# HSM_HSM_TRNG_CE00A000h register map
Vendor: Texas Instruments
Peripheral module from a debugger description file (folder AM263P).
Registers are 32-bit, access per field, reset 0x0 unless marked. A register's access mark holds for its fields unless they carry their own. Offsets are as the file gives them; lines under a group give offsets from that group; [hi:lo] are bit positions; {n}, {i} and the like mark numbered series; 'fields as' and 'values as' point back to an identical list; <NAME> marks a mode.

## HSM_TRNG
{0x0+4i} HSM_TRNG_TRNG_INPUT_{i} rw (i=0..3) — These registers are used as input for [SP 800-90A] AES-256 DRBG testing. They share theiraddresses with the TRNG_OUTPUT_0 to TRNG_OUTPUT_3 registers.
  [31:0] TRNG_INPUT — These registers are used as input for [SP 800-90A] AES-256 DRBG testing.
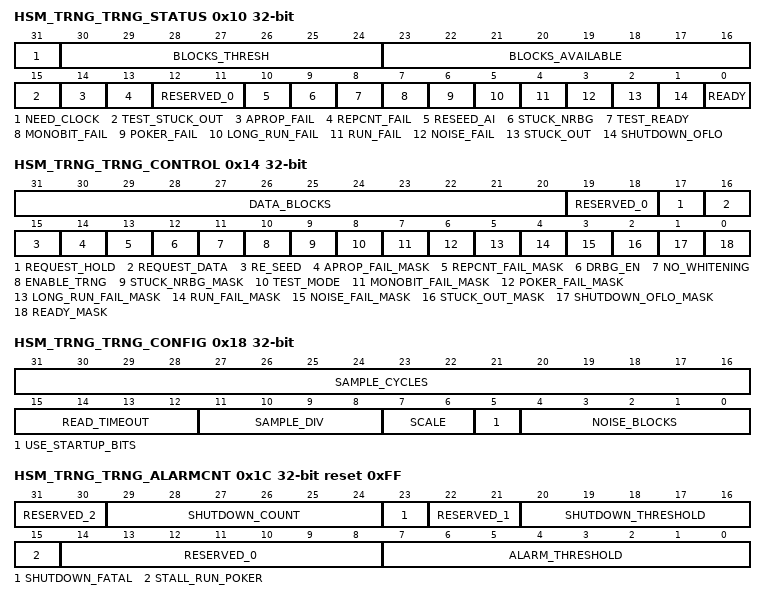
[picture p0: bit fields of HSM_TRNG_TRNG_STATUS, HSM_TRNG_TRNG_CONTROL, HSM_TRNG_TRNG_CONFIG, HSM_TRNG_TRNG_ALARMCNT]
0x10 HSM_TRNG_TRNG_STATUS — Status register.
  [31] NEED_CLOCK ro — 1' indicates that the TRNG is busy generating entropy or is in one of its test modes - the module clock may not be turned off. This bit is a direct mirror of the 'need_clock'output signal of the module.
  [30:24] BLOCKS_THRESH ro — The threshold value for the 'blocks_available' field to indicate 'ready' here. The value iswritten via bits [30:24] of the TRNG_INTACK register. The number of blocks availablein the RAM buffer must be equal to or greater than the value in this field [which iscontrolled by Writing to the TRNG_INTACK register].Note: This field controls the data available interrupt [and status] gating based on thefill level of the RAM buffer. When the interrupt occurs, there is always one extraword available in the output register - with a value of 15 here, the number ofwords that are available is 16 when data ready is indicated.
  [23:16] BLOCKS_AVAILABLE ro — This field indicates the number of 128 bits blocks of random data that are available inthe random data RAM buffer [if configured]. If this value is non-zero, the outputregisters will be re-filled from the random data RAM buffer immediately afteracknowledging the 'ready' interrupt [i.e. after Writing a '1' to bit [0] of theTRNG_INTACK register].
  [15] TEST_STUCK_OUT ro — 1' = indication that 'stuck_out' functionality testing is enabled [via TRNG_INTACKregister bit [15]]. This bit will automatically fall back to '0' when a stuck output isactually detected.
  [14] APROP_FAIL ro — 1' = the [SP 800-90B] 'Adaptive Proportion' test logic monitoring the data shifted intothe main shift register detected too many 8-bit Noise Source output samples matchingthe first sample taken in the test window. Bits [31:30] of the TRNG_SPB_TESTSregister indicate which of the two 'Adaptive Proportion' tests detected the error.Writing a '1' to bit [14] of the TRNG_INTACK register clears this bit to '0', also clearsbits [31:30] of the TRNG_SPB_TESTS register.
  [13] REPCNT_FAIL ro — 1' = the [SP 800-90B] 'Repetition Count' test logic monitoring the data shifted into themain shift register detected a number of consecutive identical 8-bit Noise Source outputsamples that matched the programmed cutoff value. Writing a '1' to bit [13] of theTRNG_INTACK register clears this bit to '0'.
  [12:11] RESERVED_0 wo — Bits should be ignored on a read.
  [10] RESEED_AI ro — For the EIP-76d configurations with BC_DF functionality, this bit indicates when theTRNG_PS_AI_ - registers must be written for an 'Instantiate' or 'Reseed' operation[Writing the highest Byte of the TRNG_PS_AI_11 register then clears this bit]. This bitalso indicates when the DRBG has finished updating its internal Key and V values aftergenerating random data; no specific action is required at that time.Note: This bit is only available for EIP-76d configurations with BC_DF; otherwise, itmust be treated as 'Reserved'.
  [9] STUCK_NRBG ro — 1' = NRBG stuck error; this happens when two identical values were extracted fromthe main shift register [configuration without Conditioning Function] or theConditioning Function output [when configured].
  [8] TEST_READY ro — Multi-purpose bit:> For known-answer tests on the 'Repetition Count', 'Adaptive Proportion','monobit', 'run' and 'poker' tests, BC_DF functionality and Conditioning Function,a '1' indicates that data can be written to the TRNG_RAW_... registers.> When testing the DRBG, a '1' indicates that test data can be written to theTRNG_INPUT_ - registers [for separate AES core testing], result data can be readfrom the TRNG_OUTPUT_ - registers when this bit has become '1' again afterdropping to '0'.> When testing the Noise Source, a '1' indicates that a 64 bit output block from theNoise Source is available for Reading from the TRNG_RAW_... registers, Writing a'1' to the 'test_ready_ack' bit in the TRNG_ACK register will then clear this bitagain.> For the EIP-76d configurations without BC_DF, a '1' here indicates when theTRNG_PS_AI_ - registers can be written to set an Additional Input value for a'Generate' operation. It also indicates when those registers must be written for a'Reseed' operation or [SP 800-90A] DRBG tests. Writing the highest Byte of theTRNG_PS_AI_11 register then clears this bit.Note: For the EIP-76d configurations with BC_DF, the indication that theTRNG_PS_AI_ - registers must be written for an 'Instantiate' or 'Reseed'operation is split off, see bit [10].
  [7] MONOBIT_FAIL ro — 1' = the [AIS-31] 'monobit test' logic monitoring data shifted into the main shiftregister detected an out-of-bounds number of '1's after checking 20,000 bits [test T1 asspecified in the [AIS-31] standard]. Writing a '1' to bit [7] of the TRNG_INTACKregister clears this bit to '0'.Note: This bit is only available if AIS-31 testing logic is configured; otherwise, it mustbe treated as 'Reserved'.
  [6] POKER_FAIL ro — 1' = the [AIS-31] 'poker test' logic monitoring data shifted into the main shift registerdetected an out-of-bounds value in at least one of the 16 'poker_count_X' counters or anout of bounds 'sum of squares' value after checking 20,000 bits [test T2 as specified inthe [AIS-31] standard]. Writing a '1' to bit [6] of the TRNG_INTACK register clears thisbit to '0'.Note: This bit is only available if AIS-31 testing logic is configured; otherwise, it mustbe treated as 'Reserved'.
  [5] LONG_RUN_FAIL ro — 1' = the [AIS-31] 'run test' logic monitoring data shifted into the main shift registerdetected a sequence of 34 identical bits [test T4 as specified in the [AIS-31] standard].Writing a '1' to bit [5] of the TRNG_INTACK register clears this bit to '0'.Note: This bit is only available if AIS-31 testing logic is configured; otherwise, it mustbe treated as 'Reserved'.
  [4] RUN_FAIL ro — 1' = the [AIS-31] 'run test' logic monitoring data shifted into the main shift registerdetected an out-of-bounds value for at least one of the 'run_X_count_...' counters afterchecking 20,000 bits [test T3 as specified in the [AIS-31] standard]. Writing a '1' to bit[4] of the TRNG_INTACK register clears this bit to '0'.Note: This bit is only available if AIS-31 testing logic is configured; otherwise, it mustbe treated as 'Reserved'.
  [3] NOISE_FAIL ro — 1' = the [AIS-31] 'run test' logic monitoring data shifted into the main shift registerdetected a sequence of 48 identical bits, which is considered a 'Noise Source failure' asproposed in section E.5 of the [AIS-31] standard. Writing a '1' to bit [3] of theTRNG_INTACK register clears this bit to '0'.Note: This bit is only available if AIS-31 testing logic is configured; otherwise, it mustbe treated as 'Reserved'.
  [2] STUCK_OUT ro — 1' = logic around the output data registers4 detected that the EIP-76 generates the samevalue twice in a row. The word size for this comparison is 128 bits. Writing a '1' to bit[2] of the TRNG_INTACK register clears this bit to '0'.
  [1] SHUTDOWN_OFLO ro — 1' = the number of FROs shut down after a second 'error event' [i.e. the number of '1'bits in the TRNG_ALARMSTOP register] has exceeded the threshold set by'shutdown_threshold' in the TRNG_ALARMCNT register. Writing a '1' to bit [1] of theTRNG_INTACK register clears this bit to '0'.Note: This bit will be set to '1' when automatic detuning is enabled and an automaticdetuning is performed by the internal logic. In that case, the TRNG is notactually shut down and this bit is informative only.
  [0] READY ro — 1' = data is available in the TRNG_OUTPUT_0 - 3 registers. Acknowledging this stateby Writing a '1' to bit [0] of the TRNG_INTACK register clears this bit to '0'. If a newnumber is already available in the random data buffer, that number is directly movedinto the result register. In this case the 'ready' status bit is asserted again, after at mostsix module clock cycles.
0x14 HSM_TRNG_TRNG_CONTROL — Control register.
  [31:20] DATA_BLOCKS rw — This field indicates the number of 128 bit data blocks that must be generated by the [SP800-90A] AES-256 DRBG in a single 'Generate_function'. It is loaded in a write to thisregister where the 'request_data' bit is '1' [and the 're_seed' bit is '0'] and then countsdown to zero by one for each block that is generated. It is allowed to 'short-cycle' a'Generate_function' by Writing a lower value than already present [even value zero],but Writing a larger value than already present is not allowed [unless the field equalszero]. The maximum number of blocks that can be requested in one go 4095 preventsrequesting too much data in a single 'Generate_function', which is limited by SP 800-90A to generate no more than 219 bits per request.Note: This field is only present when an SP 800-90A DRBG is available.Note: This field covers Bytes 2 and 3 of this register and these Bytes must either bewritten in one go or using the 'request_hold' bit if the Byte write functionality isconfigured [which it is by default].Note: When aborting a 'Generate_function' by Writing zero here, the word beinggenerated at that time is completed normally and stored in the output buffermodule.
  [19:18] RESERVED_0 wo — Bits should be written with '0' and should be ignored on a read.
  [17] REQUEST_HOLD rw — Read/write, this bit can only be set to '1' when the 'data_blocks' field has value zero andByte Writing only bits [23:16], setting the 'request_data' bit to '1' and loading bits[23:20] of the 'data_blocks' field. Value '1' in this bit indicates that bits [31:24] of the'data_blocks' field must be loaded with a separate Byte write, at which point this bit fallsback to '0' and the actual 'Generate_function' is started. Any other write of this registerwith this bit at '1' clears this bit but also clears the buffered 'data_blocks' value.Note: This bit is only present when an [SP 800-90A] AES-256 DRBG is available andByte Writing is configured [the latter is the default].
  [16] REQUEST_DATA rw — Write-only, Writing a '1' indicates that the 'data_blocks' field contains the number of128 bit data blocks that the [SP 800-90A] AES-256 DRBG should generate in a single'Generate_function'. Writing a '0' has no effect.Note: This bit is only present when an SP 800-90A AES-256 DRBG is available andcan only be set to '1' when 'enable_trng' and 'drbg_en' were '1' before thewrite.Note: When Writing a '1' here, only the 'data_blocks' field in this register is changed.Re-seeding takes priority over data generation.Note: When Byte-Writing only bits [23:16] with this bit at '1' and 'request_hold' at '0',bits [31:24] of the 'data_blocks' field are cleared to zeroes.
  [15] RE_SEED rw — Set-only, Writing a '1' starts a 'Reseed' as described in section 5.2.5.4 below, Writing a'0' has no effect.This bit falls back to '0' automatically after the 'Reseed' operation is complete - at thattime the 'block_count' field in the TRNG_BLOCKCNT register is reset to zero and therandom data buffer is zeroized so that any new data read from the EIP-76 will use thenew seed values.Note: This bit is only present when an [SP 800-90A] AES-256 DRBG is available andcan only be set to '1' when 'enable_trng' and 'drbg_en' were '1' before thewrite.Note: When Writing a '1' here, all other bits in this register remain unchanged. Reseedingtakes priority over data generation.
  [14] APROP_FAIL_MASK rw — 1' = allow the 'aprop_fail' bit in the TRNG_STATUS register to activate the [active'high'] 'irq' output.
  [13] REPCNT_FAIL_MASK rw — 1' = allow the 'repcnt_fail' bit in the TRNG_STATUS register to activate the [active'high'] 'irq' output.
  [12] DRBG_EN rw — Enable the [SP 800-90A] AES-256 DRBG. If this bit is reset to '0', the DRBG is forcedback into the idle state immediately.Note: This bit is only present when the SP 800-90A AES-256 DRBG is available andcan only be changed when 'enable_trng' was '0' before the write.To change this bit during operation, it is required to first put the EIP-76 into reset['enable_trng' = 0]. If the DRBG is enabled, it can be disabled by a subsequent write of'0' to 'drbg_en' [Writing this bit when 'enable_trng' is still '1' has no effect, so itrequires TWO writes to this register to disable the DRBG in that case]. The DRBG thenstops immediately. To enable it, the 'drbg_en' bit must be written with '1'. Afterchanging the state, the EIP-76 must be started again by setting the 'enable_trng' bit to'1'. Note that it is required to re-gather entropy, so the same number of start-up cycleswill be used as when starting the EIP-76 out of a system reset state.
  [11] NO_WHITENING rw — The default value of '0' means that toggle-flop whitening of the noise source is enabled.Set this bit to '1' to disable the toggle flip-flop based whitening of the noise source, seesection 3.2 for details. In this mode, the sampling interval is the number of clocksspecified in sample_div multiplied by the factor specified in sample_cycles [and scale].
  [10] ENABLE_TRNG rw — Setting this bit to '1' starts the EIP-76, gathering entropy from the FROs. Resetting thisbit to '0' forces all NRBG logic back into the idle state immediately.For the [SP 800-90A] DRBG option, starting the EIP-76 with the 'drbg_en' bit value '1'performs a CTR_DRBG 'Instantiate' operation [with or without BC_DF, as perconfiguration] with a 'Personalization String' as written to the TRNG_PS_AI_...registers at that time. Resetting this bit to '0' performs the 'Un-instantiate' operation,clearing all internal post-processor registers.
  [9] STUCK_NRBG_MASK rw — 1' = allow the 'stuck_nrbg' bit in the TRNG_STATUS register to activate the [active'high'] 'irq' output.
  [8] TEST_MODE rw — 1' = Enables access to [amongst others] the TRNG_COUNT and TRNG_RAW_L/Hregisters [the latter are cleared before enabling access] and keep 'need_clock' outputactive 'high' for testing purposes. This bit must be set to '1' before various test modesin the TRNG_TEST register can be enabled [see section 5.2.21].
  [7] MONOBIT_FAIL_MASK rw — 1' = allow the 'monobit_fail' bit in the TRNG_STATUS register to activate the [active'high'] 'irq' output.Note: This bit is only available if AIS-31 testing logic is configured, otherwise it mustbe treated as 'Reserved'.
  [6] POKER_FAIL_MASK rw — 1' = allow the 'poker_fail' bit in the TRNG_STATUS register to activate the [active'high'] 'irq' output.Note: This bit is only available if AIS-31 testing logic is configured, otherwise it mustbe treated as 'Reserved'
  [5] LONG_RUN_FAIL_MASK rw — 1' = allow the 'long_run_fail' bit in the TRNG_STATUS register to activate the [active'high'] 'irq' output.Note: This bit is only available if AIS-31 testing logic is configured, otherwise it mustbe treated as 'Reserved'.
  [4] RUN_FAIL_MASK rw — 1' = allow the 'run_fail' bit in the TRNG_STATUS register to activate the [active 'high']'irq' output.Note: This bit is only available if AIS-31 testing logic is configured, otherwise it mustbe treated as 'Reserved'.
  [3] NOISE_FAIL_MASK rw — 1' = allow the 'noise_fail' bit in the TRNG_STATUS register to activate the [active'high'] 'irq' output.Note: This bit is only available if AIS-31 testing logic is configured, otherwise it mustbe treated as 'Reserved'.
  [2] STUCK_OUT_MASK rw — 1' = allow the 'stuck_out' bit in the TRNG_STATUS register to activate the [active'high'] 'irq' output.
  [1] SHUTDOWN_OFLO_MASK rw — 1' = allow the 'shutdown_oflo' bit in the TRNG_STATUS register to activate the [active'high'] 'irq' output.
  [0] READY_MASK rw — 1' = allow the 'ready' bit in the TRNG_STATUS register to activate the [active 'high']'irq' output.
0x18 HSM_TRNG_TRNG_CONFIG rw — Configuration register.
  [31:16] SAMPLE_CYCLES — This field, together with the 'scale' field, defines the number of clock cycles beforeshifting the main shift register and thereby freezing the noise sample. This value mustbe such that there is at least one bit of entropy [in total] in each 8 bits that are shifted.When the 'no_whitening' bit in the TRNG_CONTROL register is set, only the last FROsample is taken and shifted in. When the 'no_whitening' bit is not set, a FRO sample istaken every clock cycle and accumulated via XOR before finally shifting it in.This field can only be modified while 'enable_trng' in TRNG_CONTROL is '0' or wheneither of the 'test_known_noise' or 'test_cond_func' bits in TRNG_TEST is '1'. Value 0 inthis field selects 65536 * 4^scale clock cycles between shifting.
  [15:12] READ_TIMEOUT — This field controls the secure Reading mode [see section 5.2.6.2]. Value 0 disablessecure Reading, values in the range 1 - 15 enable secure Reading and set a read gateclosure timeout of approximately [read_timeout] x 16 'clk' input cycles.This field can only be modified while 'enable_trng' in TRNG_CONTROL is '0'.
  [11:8] SAMPLE_DIV — This field directly controls the number of 'clk' input cycles between samples takenfrom the FROs. The default value 0 indicates that samples are taken every 'clk' cycle,maximum value 15 [decimal] takes one sample every 16 'clk' cycles.This field must be set to a value such that the slowest FRO [even under worst-caseconditions] has a cycle time less than twice the sample period. As delivered, the defaultconfiguration of the FROs should allow this field to remain 0 - this must, however, beconfirmed with post-placement and routing timing analysis.This field can only be modified while 'enable_trng' in TRNG_CONTROL is '0' or wheneither of the 'test_known_noise' or 'test_cond_func' bits in TRNG_TEST is '1'.
  [7:6] SCALE — This field sets the scale factor for the 'sample_cycles' value:0 -> number of XOR-ed FRO samples equals 'sample_cycles'1 -> number of XOR-ed FRO samples equals 'sample_cycles' x 42 -> number of XOR-ed FRO samples equals 'sample_cycles' x 163 -> number of XOR-ed FRO samples equals 'sample_cycles' x 64This field can only be modified while 'enable_trng' in TRNG_CONTROL is '0' or wheneither of the 'test_known_noise' or 'test_cond_func' bits in TRNG_TEST is '1'.
  [5] USE_STARTUP_BITS — Do not discard the first 512 bits of raw data. This reduces the start-up time, but maymore frequently cause start-up health test failures.For configurations without Conditioning function: When enabled, the first 128 bits willstill be discarded instead.
  [4:0] NOISE_BLOCKS — This field sets the number of 512-bit blocks of raw Noise Source output data that mustbe processed by either the Conditioning Function or the SP 800-90 DRBG 'BC_DF'functionality to yield a 'full entropy' output value. As according to [SP 800-90B] theamount of entropy input to this functionality must be twice the amount that is outputand the 8-bit samples output by the Noise Source are supposed to have one bit ofentropy each, the settings for this field are as follows:> SHA-1 Conditioning Function: generates 160 bits output, requiring2560samplebits, equivalent to 5 blocks of raw Noise Source input.> SHA-256 Conditioning Function: generates 256 bits output, requiring4096samplebits, equivalent to 8 blocks of raw Noise Source input. Note that two blocks of 256bits are needed to 'Instantiate' or 'Reseed' the SP 800-90 DRBG [in the EIP-76d-*-SHA2 configurations].> SP 800-90 DRBG 'BC_DF' functionality: generates 384 bits output, requiring6144sample bits, equivalent to 12 blocks of raw Noise Source input.This field can only be modified while 'enable_trng' in TRNG_CONTROL is '0' or wheneither of the 'test_known_noise' or 'test_cond_func' bits in TRNG_TEST is '1'. Value 0 inthis field selects 32 blocks of 512 bits to be processed.
0x1C HSM_TRNG_TRNG_ALARMCNT reset 0xFF — Shutdown interr. ctrl register.
  [31:30] RESERVED_2 wo — Bits should be written with a '0' and should be ignored on a read.
  [29:24] SHUTDOWN_COUNT rw — Read-only, indicates the number of '1' bits in the TRNG_ALARMSTOP register.This field is 6 bits wide to allow up to 32 'ones' to be indicated. The actual maximumvalue equals the number of FROs.
  [23] SHUTDOWN_FATAL rw — 1' = Consider the 'shutdown_oflo' interrupt as a fatal error requiring taking the completeTRNG engine off-line
  [22:21] RESERVED_1 wo — Bits should be written with a '0' and should be ignored on a read.
  [20:16] SHUTDOWN_THRESHOLD rw — Threshold setting for generating the 'shutdown_oflo' interrupt, which is activated whenthe 'shutdown_count' value in this register exceeds the threshold value set here.
  [15] STALL_RUN_POKER rw — 1' = Stall the 'monobit test', 'run test' and 'poker test' circuits when either the'monobit_fail', 'run_fail' or 'poker_fail' bits in the TRNG_STATUS register are set to '1' - this allows inspecting the state of the result counters [which would otherwise be resetimmediately for the next 20,000 bits block to test].
  [14:8] RESERVED_0 wo — Bits should be written with a '0' and should be ignored on a read.
  [7:0] ALARM_THRESHOLD rw — Alarm detection threshold for the repeating pattern detectors on each FRO. A FRO'alarm event' is declared when a repeating pattern [of up to four samples length] isdetected continuously for the number of samples defined by this field's value. Resetvalue 255 [decimal] should keep the number of 'alarm events' to a manageable level.
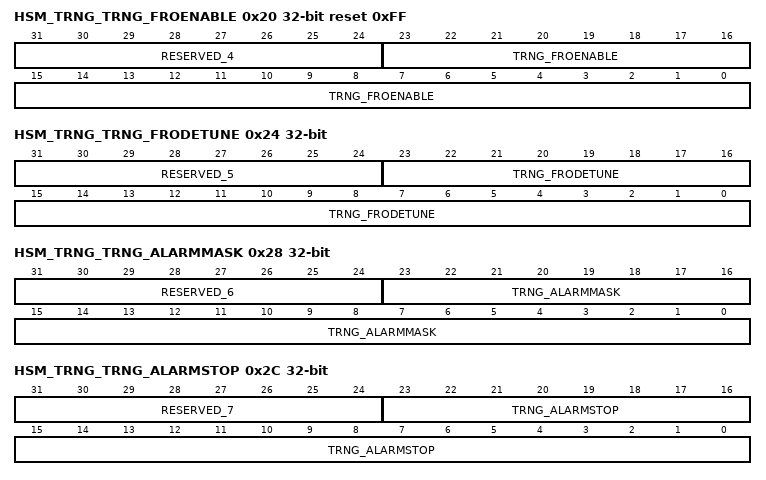
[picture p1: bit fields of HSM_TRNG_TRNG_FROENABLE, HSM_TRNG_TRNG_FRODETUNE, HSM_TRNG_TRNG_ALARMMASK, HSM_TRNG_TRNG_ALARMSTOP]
0x20 HSM_TRNG_TRNG_FROENABLE reset 0xFF — FRO enables register.
  [31:24] RESERVED_4 wo — Bits should be written with a '0' and should be ignored on a read.
  [23:0] TRNG_FROENABLE rw — Enable bits for the individual FROs. A '1' in bit [n] enables FRO 'n'. The default stateis all ones to enable all FROs after power-up. Note that they are not actually started upbefore the 'enable_trng' bit in the TRNG_CONTROL register is set to '1'. A bit isautomatically forced to '0' here [and cannot be written to '1'] when the correspondingbit in the TRNG_ALARMSTOP register has value '1'.
0x24 HSM_TRNG_TRNG_FRODETUNE — FRO de-tune bits register.
  [31:24] RESERVED_5 wo — Bits should be written with a '0' and should be ignored on a read.
  [23:0] TRNG_FRODETUNE rw — De-tune bits for the individual FROs. A '1' in bit [n] lets FRO 'n' run approximately5 0.000000aster. The value of one of these bits may only be changed while the correspondingFRO is turned off [by temporarily Writing a '0' in the corresponding bit of theTRNG_FROENABLE register].
0x28 HSM_TRNG_TRNG_ALARMMASK — Alarm event log register.
  [31:24] RESERVED_6 wo — Bits should be written with a '0' and should be ignored on a read.
  [23:0] TRNG_ALARMMASK rw — Logging bits for the 'alarm events' of individual FROs. A '1' in bit [n] indicates FRO'n' experienced an 'alarm event'.
0x2C HSM_TRNG_TRNG_ALARMSTOP — Alarm shutdown register.
  [31:24] RESERVED_7 wo — Bits should be written with a '0' and should be ignored on a read.
  [23:0] TRNG_ALARMSTOP rw — Logging bits for the 'alarm events' of individual FROs. A '1' in bit [n] indicates FRO'n' experienced more than one 'alarm event' in quick succession and has been turnedoff. A '1' in this field forces the corresponding bit in the TRNG_FROENABLE registerto '0'.
0x30 HSM_TRNG_TRNG_RAW_L rw — Raw noise bits [31:0].
  [31:0] TRNG_RAW_L — When 'test_mode' in TRNG_CONTROL = '1', 'test_noise' in TRNG_TEST = '1' and'test_shiftreg' in TRNG_TEST = '0': read-only access to the main shift register's readbuffer register bits [31:0].When 'test_mode' in TRNG_CONTROL = '1', 'test_noise' in TRNG_TEST = '1' and'test_shiftreg' in TRNG_TEST = '1': read-only access to main shift register bits [31:0].When 'test_mode' in TRNG_CONTROL = '1' and 'test_known_noise' in TRNG_TEST ='1': write-only access to main shift register bits [31:0] [read buffer register bits [31:0]are also written with the same value but generally not used].
0x34 HSM_TRNG_TRNG_RAW_H rw — Raw noise bits [63:32].
  [31:0] TRNG_RAW_H — When 'test_mode' in TRNG_CONTROL = '1', 'test_noise' in TRNG_TEST = '1' and'test_shiftreg' in TRNG_TEST = '0': read-only access to the main shift register's readbuffer register bits [63:32].When 'test_mode' in TRNG_CONTROL = '1', 'test_noise' in TRNG_TEST = '1' and'test_shiftreg' in TRNG_TEST = '1': read-only access to main shift register bits [63:32].When 'test_mode' in TRNG_CONTROL = '1' and 'test_known_noise' in TRNG_TEST ='1': write-only access to main shift register bits [63:32] [read buffer register bits [63:32]are also written with the same value value but generally not used].
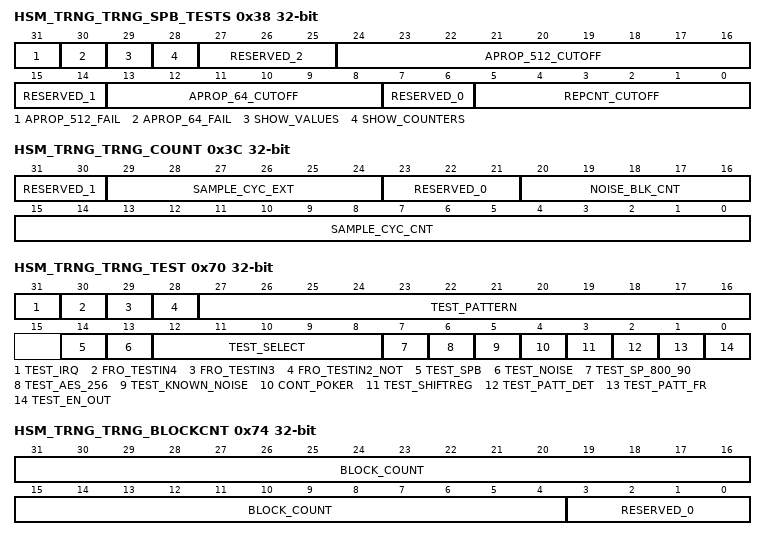
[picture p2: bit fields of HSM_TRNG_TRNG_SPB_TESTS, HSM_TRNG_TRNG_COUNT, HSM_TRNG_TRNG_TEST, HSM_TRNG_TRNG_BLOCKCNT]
0x38 HSM_TRNG_TRNG_SPB_TESTS — SP 800-90B tests control/state.
  [31] APROP_512_FAIL rw — Bit indicating that the 'aprop_512_counter' was equal to the 'aprop_512_cutoff' setting.The state of this bit is OR-ed with the 'aprop_64_fail' bit into the 'aprop_fail' bit in theTRNG_STATUS register and cleared to '0' when Writing a '1' to the 'aprop_fail_ack' bitof the TRNG_INTACK register. While normally read-only, this bit can be written when'test_spb' in TRNG_TEST is '1'.
  [30] APROP_64_FAIL rw — Bit indicating that the 'aprop_64_counter' was equal to the 'aprop_64_cutoff' setting. Thestate of this bit is OR-ed with the 'aprop_512_fail' bit into the 'aprop_fail' bit in theTRNG_STATUS register and cleared to '0' when Writing a '1' to the 'aprop_fail_ack' bitof the TRNG_INTACK register. While normally read-only, this bit can be written when'test_spb' in TRNG_TEST is '1'.
  [29] SHOW_VALUES rw — Bit controlling what is actually accessible in this register; can only be set to '1' when'test_spb' in TRNG_TEST is '1'. When Writing this bit to a different value, all other bitsin this register are preserved.When Writing both 'show_counters' and 'show_values' with a '1' while 'test_spb' inTRNG_TEST is '1', all bits in this register are preserved but the 12-bit internal cyclecounter for the 'Adaptive Proportion' tests is reset to its initial state.
  [28] SHOW_COUNTERS rw — Bit controlling what is actually accessible in this register; can only be set to '1' when'show_values' is written '0' and 'test_spb' in TRNG_TEST is '1'. When Writing this bitto a different value all other bits in this register are preserved.When Writing both 'show_counters' and 'show_values' with a '1' while 'test_spb' inTRNG_TEST is '1', all bits in this register are preserved but the 12-bit internal cyclecounter for the 'Adaptive Proportion' tests is reset to its initial state.
  [27:25] RESERVED_2 wo — Bits should be written with a '0' and should be ignored on a read while 'show_values'equals '1'.
  [24:16] APROP_512_CUTOFF rw — Adaptive Proportion' test cutoff value for the 512 Noise Source samples window sizetest, accessible when 'show_counters' and 'show_values' are both '0'. The reset value of325 corresponds to the cutoff value for a false positive rate of 2-30 and 1 bit of entropyper 8-bit Noise Source sample. This field can only be modified while 'enable_trng' inTRNG_CONTROL is '0' or 'test_spb' in TRNG_TEST is '1'. Value 0 in this fielddisables the 'Adaptive Proportion' test with 512 Noise Source samples window size.
  [15:14] RESERVED_1 wo — Bits should be written with a '0' and should be ignored on a read while 'show_values'equals '0'.
  [13:8] APROP_64_CUTOFF rw — Adaptive Proportion' Noise Source sample compare value for the 64 Noise Sourcesamples window size test, accessible when 'show_values' is '1'. This field is writeablefor testing purposes.
  [7:6] RESERVED_0 wo — Bits should be written with a '0' and should be ignored on a read while 'show_values'equals '0'.
  [5:0] REPCNT_CUTOFF rw — Repetition Count' test cutoff value, accessible when 'show_counters' and 'show_values'are both '0'. The reset value of 31 corresponds to the cutoff value for a false positiverate of 2-30 and 1 bit of entropy per 8-bit Noise Source sample. This field can only bemodified while 'enable_trng' in TRNG_CONTROL is '0' or 'test_spb' in TRNG_TEST is'1'. Value 0 in this field disables the 'Repetition Count' test.
0x3C HSM_TRNG_TRNG_COUNT — Main timing counters register.
  [31:30] RESERVED_1 wo — Bits should be written with a '0' and should be ignored on a read.
  [29:24] SAMPLE_CYC_EXT rw — Extension bits for the sample cycle counter, used when the 'scale' field in theTRNG_CONFIG register is non-zero. This counter can only be accessed when the'test_mode' bit in TRNG_CONTROL is set to '1'.
  [23:21] RESERVED_0 wo — Bits should be written with a '0' and should be ignored on a read.
  [20:16] NOISE_BLK_CNT rw — Noise blocks counter used to control the number of 512-bits noise blocks to be handledby the SHA-1/SHA-256 Conditioning Function or BC_DF functionality in the SP 800-90A DRBG [depending on configuration]. The start value of this counter is 1, which isalso the value to which it is reset when it reaches the value of the 'noise_blocks' field inthe TRNG_CONFIG register. This counter can only be accessed when 'test_mode' bit inTRNG_CONTROL is set to '1', restricted to read-only accesses when the 'test_noise' bitin the TRNG_TEST register is '1'.
  [15:0] SAMPLE_CYC_CNT rw — Lowest 16 bits of the sample cycle counter used to control the number of [XOR-ed]FRO samples that are XOR-ed together into a single noise bit. The start value of thiscounter is 1, which is also the value to which it is reset when it reaches the valuedefined by the 'sample_cycles' and 'scale' fields in the TRNG_CONFIG register. Thiscounter can only be accessed when the 'test_mode' bit in TRNG_CONTROL is set to '1'.Note: If the 'no_whitening' bit in the TRNG_CONTROL register is set to '1', the XORingof FRO samples is not done; the noise bit is then the last FRO sample of theinterval timed by this counter.
0x40 HSM_TRNG_TRNG_PS_AI_0 wo — DRBG input (LSW).
  [31:0] VECTOR — Bits [31:0] of the SP 800-90A 'Personalization String'/'Nonce' [Instantiate function] or'Additional Input' [Reseed and Generate functions]. This register is only availablewhen an SP 800-90A DRBG is configured.
{0x40+4i} HSM_TRNG_TRNG_PS_AI_{i} wo (i=1..3) — DRBG input.
  [31:0] VECTOR — Bits [{32i+31}:{32i}] of the SP 800-90A 'Personalization String'/'Nonce' [Instantiate function]or 'Additional Input' [Reseed and Generate functions]. This register is only availablewhen an SP 800-90A DRBG is configured.
0x50 HSM_TRNG_TRNG_PS_AI_4 wo — DRBG input.
  [31:0] VECTOR — Bits [159:128] of the SP 800-90 'Personalization String'/'Nonce' [Instantiate function]or 'Additional Input' [Reseed and Generate functions]. This register is only availablewhen an SP 800-90 DRBG is configured.
0x54 HSM_TRNG_TRNG_PS_AI_5 wo — DRBG input.
  [31:0] VECTOR — Bits [191:160] of the SP 800-90A 'Personalization String'/'Nonce' [Instantiate function]or 'Additional Input' [Reseed and Generate functions]. This register is only availablewhen an SP 800-90A DRBG is configured.
0x58 HSM_TRNG_TRNG_PS_AI_6 wo — DRBG input.
  [31:0] VECTOR — Bits [223:192] of the SP 800-90A 'Personalization String'/'Nonce' [Instantiate function]or 'Additional Input' [Reseed and Generate functions]. This register is only availablewhen an SP 800-90A DRBG is configured.
0x5C HSM_TRNG_TRNG_PS_AI_7 wo — DRBG input.
  [31:0] VECTOR — Bits [255:224] of the SP 800-90 'Personalization String'/'Nonce' [Instantiate function]or 'Additional Input' [Reseed and Generate functions]. This register is only availablewhen an SP 800-90 DRBG is configured.
0x60 HSM_TRNG_TRNG_PS_AI_8 wo — DRBG input.
  [31:0] VECTOR — Bits [287:256] of the SP 800-90A 'Personalization String'/'Nonce' [Instantiate function]or 'Additional Input' [Reseed and Generate functions]. This register is only availablewhen an SP 800-90A DRBG is configured.
0x64 HSM_TRNG_TRNG_PS_AI_9 wo — DRBG input.
  [31:0] VECTOR — Bits [319:288] of the SP 800-90 'Personalization String'/'Nonce' [Instantiate function]or 'Additional Input' [Reseed and Generate functions]. This register is only availablewhen an SP 800-90 DRBG is configured.
0x68 HSM_TRNG_TRNG_PS_AI_10 wo — DRBG input.
  [31:0] VECTOR — Bits [351:320] of the SP 800-90A 'Personalization String'/'Nonce' [Instantiate function]or 'Additional Input' [Reseed and Generate functions]. This register is only availablewhen an SP 800-90A DRBG is configured.
0x6C HSM_TRNG_TRNG_PS_AI_11 wo — DRBG input (MSW).
  [31:0] VECTOR — Bits [383:352] of the SP 800-90A 'Personalization String'/'Nonce' [Instantiate function]or 'Additional Input' [Reseed and Generate functions]. This register is only availablewhen an SP 800-90A DRBG is configured.Note: This register must be written with a [dummy] value for a 'Reseed' operation tocomplete. For BC_DF configurations, it must also be written for an'Instantiate' function.
0x70 HSM_TRNG_TRNG_TEST rw — Test control register.
  [31] TEST_IRQ — 1' = force 'irq' output 'high' for interrupt signal connectivity testing.
  [30] FRO_TESTIN4 — Control bit driving the 'fro_testin4' output of the TRNG module, which connects to allthe select inputs on the test multiplexers in the FROs [see Figure 3]. The actual outputhas the state of this bit, so a '0' selects the output of the delay control multiplexers. A'1' here also forces the 'fro_enable[n]' output [with n equal to the value of the'test_select' field here] to '1' - this allows testing the signal path through the AND-ORINVERTgate in the FROs.This bit can only be set to '1' when 'test_mode' in TRNG_CONTROL is '1' too.
  [29] FRO_TESTIN3 — Control bit driving the 'fro_testin3' output of the TRNG module, which connects to allthe OR inputs on the AND-OR gates in the FRO chains [see Figure 3]. The actualoutput has the state of this bit, so a '0' does not disturb the operation of the FROs.This bit can only be set to '1' when 'test_mode' in TRNG_CONTROL is '1' too.
  [28] FRO_TESTIN2_NOT — Control bit driving the 'fro_testin2' output of the TRNG module, which connects to allthe AND inputs on the AND-OR gates in the FRO chains [see Figure 3]. The actualoutput is the complement of this bit, so a '0' does not disturb the operation of the FROs.This bit can only be set to '1' when 'test_mode' in TRNG_CONTROL is '1' too.
  [27:16] TEST_PATTERN — Repeating sequence of bits to be fed into the selected FRO delay chain ['test_patt_fro' ='1'] and/or the selected FRO error detection circuit ['test_patt_det' = '1']. This field isrotated right over one bit, once every sample period, when either of these control bits is'1'. Therefore, bit [16] is the actual pattern bit fed into the test target.
  [14] TEST_SPB — 1' = Enable testing of the [SP 800-90B] 'Repetition Count' and 'Adaptive Proportion'tests by allowing the 'show_counters' and 'show_values' bits in the TRNG_SPB_TESTSregister to be set non-zero. To perform Known Answer Tests on those functions, the'test_known_noise' bit in this register must be set to '1' too. The 'need_clock' output isforced active while this bit is '1'. See section 5.2.21.2 below for more information.This bit can only be set to '1' when 'test_mode' in TRNG_CONTROL is '1' too.
  [13] TEST_NOISE — 1' = Enable Noise Source testing, making 64 bit blocks of Noise Source outputavailable in the TRNG_RAW_... registers. When 'test_shiftreg' is '0', these must beacknowledged by Writing a '1' to the 'test_ready_ack' bit in the TRNG_ACK register.The 'need_clock' output is forced active while this bit is '1'.This bit can only be set to '1' when 'test_mode' in TRNG_CONTROL is '1' and'test_known_noise' is written with a '0'.
  [12:8] TEST_SELECT — Number of the FRO to be tested, value should be in range 0 - 23 for the defaultconfiguration of 24 FROs.
  [7] TEST_SP_800_90 — 1' = Provide direct access to the [SP 800-90A] DRBG [EIP-76d] for NIST compliantknown-answer tests [DRBG state is lost during testing]. The 'need_clock' output isforced active while this bit is '1'. See section 5.2.21.4 below for more information.This bit is only present when an [SP 800-90A] DRBG is available [EIP-76d] and canonly be set to '1' when the 'drbg_en' bit in the TRNG_CONTROL register is '1' and the'test_aes_256' bit in this register is '0' before the write. For an EIP-76 configurationwithout BC_DF, an added restriction is that the 'test_known_noise' bit in this register is'0'. For configurations that include BC_DF, this test is done using known noise input tothat function, so the 'test_known_noise' bit must be '1' to set this bit.
  [6] TEST_AES_256 — Dual purpose bit that is only present when an [SP 800-90A] DRBG is available [EIP-76d] and can only be set to '1' when the 'drbg_en' bit in the TRNG_CONTROL registeris '1' and the 'test_known_noise' bit in this register is '0'.When 'test_sp_800_90' is '0':'1' = Provide direct access to the [SP 800-90A] DRBG AES-256 crypto core forknown-answer tests. The 'need_clock' output is forced active while this bit is '1'.This test mode uses TRNG_KEY_0 - TRNG_KEY_7 as key registers. Data writtento the TRNG_INPUT_ - registers is AES-ECB encrypted to the TRNG_OUTPUT_ - registers and the DRBG state is fully preserved while doing so. See section 5.2.21.4below for more information.When 'test_sp_800_90' is '1' and BC_DF functionality is not available:'0' = perform fixed sequence SP 800-90A known answer tests, each consisting ofan 'Instantiate' followed by a 'Generate with Prediction Resistance' operation.'1' = perform variable sequence SP 800-90A known answer tests, each consistingof an 'Instantiate' operation followed by any sequence of 'Reseed' and variablelength 'Generate' operations. These 'Generate' operations can be done with orwithout 'Additional Input'.While 'test_sp_800_90' is '1', 'test_aes_256' cannot be changed. 'test_aes_256' willbe forced to '0' when 'test_sp_800_90' is cleared again.
  [5] TEST_KNOWN_NOISE — 1' = Allow Writing of known test data into the main shift register [Writing input data inchunks of 64 bits to the TRNG_RAW_L and TRNG_RAW_H registers] and allow Writingof the 'noise_blocks', 'sample_interval' and 'sample_cycles' fields in the TRNG_CONFIGregister. This allows testing the [SP 800-90B] 'Repetition Count' and 'AdaptiveProportion' tests, the [optional] [AIS-31] run, poker and monobit tests, the [optional]Conditioning Function and the [SP 800-90A] BC_DF function [if configured]. Whilethis bit is '1', the Noise Source is not allowed to generate entropy but any bufferedrandom data is preserved, to be loaded into the output registers as soon as this bit isreset to '0' again. The 'need_clock' output is forced active while this bit is '1'. Allcircuits using or monitoring data in the main shift register are reset to their initial stateson any change of this bit. See section 5.2.21.1 below for more information.This bit can only be set to '1' when 'test_mode' in TRNG_CONTROL is '1' too.
  [4] CONT_POKER — 1' = Keep 'monobit test' and 'poker test' running continuously by not resetting the'monobit_count' and 'poker_count_X' counters at the end of each 20,000 bits test block.This bit can only be set to '1' when 'test_mode' in TRNG_CONTROL is '1' too.
  [3] TEST_SHIFTREG — 1' = Read directly from the main shift register when 'test_noise' is set to '1', '0' = readfrom the shift register buffer [using the 'test_ready' bit in the TRNG_STATUS register toindicate that a new batch of 64 bits can be read].This bit can only be set to '1' when 'test_mode' in TRNG_CONTROL is '1' too.
  [2] TEST_PATT_DET — 1' = Repeatedly feed 'test_pattern' into the error detection circuit of the FRO selectedby the 'test_select' field.This bit can only be set to '1' when 'test_mode' in TRNG_CONTROL is '1' too.
  [1] TEST_PATT_FR — 1' = Repeatedly feed 'test_pattern' into the delay chain of the FRO selected by the'test_select' field by forcing the corresponding 'fro_enable' output 'low' and forcingthe corresponding 'fro_testin' output to the state of bit [16] of this register.This bit can only be set to '1' when 'test_mode' in TRNG_CONTROL is '1' too.
  [0] TEST_EN_OUT — 1' = Enable the 'tst_fro_clk_out' output, connecting to the FRO selected by the'test_select' field.This bit can only be set to '1' when 'test_mode' in TRNG_CONTROL is '1' too.
0x74 HSM_TRNG_TRNG_BLOCKCNT — Output blocks counter.
  [31:4] BLOCK_COUNT rw — Counter for the number of 128-bit blocks generated by the DRBG. It is forced back tozero when the DRBG is disabled and cleared to zero when an internal 'Reseed'operation has finished. This register can be used by driver software to determine whento 'Reseed' the DRBG.The whole 32 bits of this register represent the amount of data [in bytes] generated sincethe last 'Reseed'.
  [3:0] RESERVED_0 wo — Bits should be written with a '0' and should be ignored on a read.
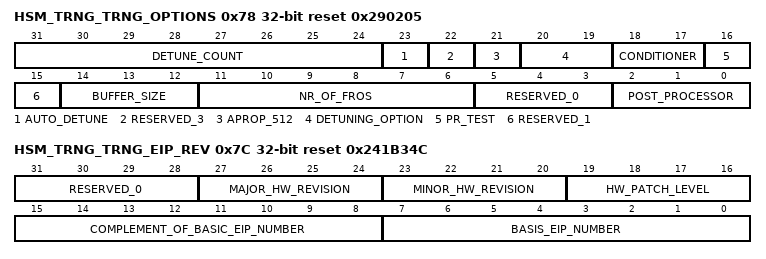
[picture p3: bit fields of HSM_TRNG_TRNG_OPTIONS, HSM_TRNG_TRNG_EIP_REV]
0x78 HSM_TRNG_TRNG_OPTIONS reset 0x290205 — Engine options information.
  [31:24] DETUNE_COUNT rw — Indicates the number of detune events that occurred on the enabled FROs. The counteris incremented by one on each detune event up to a value 255. The counter will remainat 255 when more detune events occur. The counter can be cleared by Writing value0xFF to this field [any other value has no effect].
  [23] AUTO_DETUNE rw — When written with '1', automatic detuning is enabled. For the 'basic' functionality, thedetuning is done when 'shutdown_count' exceeds 'shutdown_threshold'. At that pointFROs that have a '1' in the TRNG_ALARMSTOP register are re-enabled in theTRNG_FROENABLE register, have their detune bit flipped in the TRNG_FRODETUNEregister and their bits cleared in the TRNG_ALARMMASK and TRNG_ALARMSTOPregisters. Also, the 'shutdown_oflo' bit in the TRNG_STATUS register will be set to '1'to indicate automatic detuning has been performed.Note: This bit can only be set to '1' when the 'shutdown_fatal' field ofTRNG_ALARMCNT is configured with '0'.
  [22] RESERVED_3 wo — Bits should be ignored on a read.
  [21] APROP_512 ro — 0: [legacy] The Adaptive Proportion test works with a window size of4096bit, whichwas the size for earlier draft versions of [SP 800-90B].1:[default] The Adaptive Proportion test works with a window size of 512 bits, asspecified in [SP 800-90B].
  [20:19] DETUNING_OPTION ro — 0: no automatic detuning functionality is present1:'basic' detuning functionality is present. Default for all standard configurations.Other values are reserved
  [18:17] CONDITIONER ro — 0: no Conditioning Function is present or a BC_DF Conditioning Function is presentwhen an AES DRBG is present as well.1:a SHA1-based Conditioning Function is present.2:a SHA-256 based Conditioning Function is present.Other values are reserved.
  [16] PR_TEST ro — Indicates that Monobit, poker and run test circuits are available.
  [15] RESERVED_1 wo — Bit should be ignored on a read.
  [14:12] BUFFER_SIZE ro — Value 0 indicates no random data buffer is implemented, values 2 - 7 indicate thenumber of address bits used to address 128 bit buffer blocks in the random data buffer[so, value 2 indicates a 4 blocks/512 bits/64 Byte/16 word buffer while value 7 indicatesa 128 blocks/16K bits/2K Byte/512 word buffer]. Value 1 is reserved.This field corresponds to the value tied to the trng_buf_strap input of the EIP-76module.
  [11:6] NR_OF_FROS ro — Number of FROs implemented in this TRNG, values 24 and 8 [decimal] are standardoptions available.
  [5:3] RESERVED_0 wo — Bits should be ignored on a read.
  [2:0] POST_PROCESSOR ro — 0: no DRBG is present [EIP-76a]5:an SP 800-90A AES-256 DRBG is present [EIP-76d].Other values reserved.Note: If the DRBG option is selected without selecting a Conditioning Function[conditioner_option = 0], then the DRBG will be fitted with BC_DF functionality.
0x7C HSM_TRNG_TRNG_EIP_REV reset 0x241B34C — EIP number and core revision.
  [31:28] RESERVED_0 wo — Bits should be ignored on a read.
  [27:24] MAJOR_HW_REVISION rw — 4-bit binary encoding of the major hardware revision number.
  [23:20] MINOR_HW_REVISION rw — 4-bit binary encoding of the minor hardware revision number
  [19:16] HW_PATCH_LEVEL rw — 4-bit binary encoding of the hardware patch level, initial release will carry value zero.
  [15:8] COMPLEMENT_OF_BASIC_EIP_NUMBER rw — Bit-by-bit logic complement of bits [7:0]
  [7:0] BASIS_EIP_NUMBER rw — Bit-by-bit logic complement of bits [7:0]
